# APM32F446 register map
File version: 1.0
CPU: CM4 r0p1, little endian, MPU, FPU, 4 interrupt priority bits
Registers are 32-bit, read-write, reset 0x0 unless marked. A register's access mark holds for its fields unless they carry their own. Offsets are from the block's base; [hi:lo] are bit positions; {n}, {i} and the like mark numbered series; 'fields as' and 'values as' point back to an identical list.

## COMP — Analog Comparators
Base 0x40073000
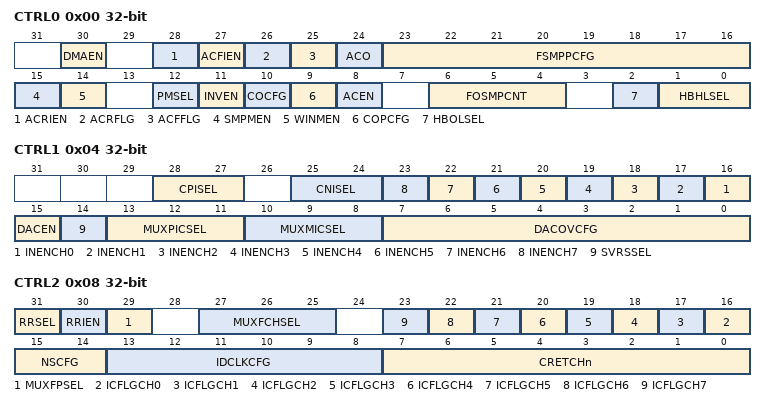
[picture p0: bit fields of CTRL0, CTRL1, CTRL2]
0x00 CTRL0 — COMP Control Register 0
  [30] DMAEN — DMA Enable
    0=DMA is disabled; 1=DMA is enabled
  [28] ACRIEN — Analog Comparator Rising Interrupt Enable
    0=Interrupt is disabled; 1=Interrupt is enabled
  [27] ACFIEN — Analog Comparator Falling Interrupt Enable
    0=Interrupt is disabled; 1=Interrupt is enabled
  [26] ACRFLG — Analog Comparator Rising Flag
    0=A rising edge has not been detected on ACO; 1=A rising edge on ACO has occurred
  [25] ACFFLG — Analog Comparator Falling Flag
    0=A falling edge has not been detected on ACO; 1=A falling edge on ACO has occurred
  [24] ACO ro — Analog Comparator Output
  [23:16] FSMPPCFG — Filter Sample Period Configure
  [15] SMPMEN — Sample Mode Enable
    0=Sampling mode is not selected; 1=Sampling mode is selected
  [14] WINMEN — Windowing Mode Enable
    0=Windowing mode is not selected; 1=Windowing mode is selected
  [12] PMSEL — Power Mode Select
    0=Low Speed (LS) comparison mode is selected; 1=High Speed (HS) comparison mode is selected, in VLPx mode, or Stop mode switched to Low Speed (LS) mode
  [11] INVEN — Invert Enable
    0=Does not invert the comparator output; 1=Inverts the comparator output
  [10] COCFG — Comparator Output Configure
    0=Set COMP to equal COUT (filtered comparator output); 1=Set COMP to equal COUTA (unfiltered comparator output)
  [9] COPCFG — Comparator Output Pin Configure
    0=When COPCFG is 0, the comparator output (after window/filter settings dependent on software configuration) is not available to a packaged pin; 1=When COPCFG is 1, and if the software has configured the comparator to own a packaged pin, the comparator is available in a packaged pin
  [8] ACEN — Analog Comparator Enable
    0=Analog Comparator is disabled; 1=Analog Comparator is enabled
  [6:4] FOSMPCNT — Filter Output Sample Count
    0=Filter is disabled. If SMPMEN = 1, then ACO is a logic zero (this is not a legal state, and is not recommended). If SMPMEN = 0, ACO = ACOA.; 1=1 consecutive sample must agree (comparator output is simply sampled); {v}={v} consecutive samples must agree (v=2..7)
  [2] HBOLSEL — Hard Block Offset Level Select
    0=The comparator hard block output has level 0 offset internally; 1=The comparator hard block output has level 1 offset internally
  [1:0] HBHLSEL — Hard Block Hysteresis Level Select
    {v}=The hard block output has level {v} hysteresis internally (v=0..3)
0x04 CTRL1 — COMP Control Register 1
  [28:27] CPISEL — Comparator Positive Input Select
    0=IN0, from the 8-bit DAC output; 1=IN1, from the analog 8-1 mux
  [25:24] CNISEL — Comparator Negative Input Select
    values as CPISEL
  [n+16] INENCH{n} (n=0..7) — Channel {n} input enable
  [15] DACEN — DAC Enable
    0=DAC is disabled; 1=DAC is enabled
  [14] SVRSSEL — Supply Voltage Reference Source Select
    0=Vin1 is selected as resistor ladder network supply reference Vin; 1=Vin2 is selected as resistor ladder network supply reference Vin
  [13:11] MUXPICSEL — Plus Input MUX Select
    {v}=IN{v} (v=0..7)
  [10:8] MUXMICSEL — Minus Input MUX Select
    {v}=IN{v} (v=0..7)
  [7:0] DACOVCFG — DAC Output Voltage Configure
0x08 CTRL2 — COMP Control Register 2
  [31] RRSEL — Round-Robin Select
    0=Round-robin operation is disabled; 1=Round-robin operation is enabled
  [30] RRIEN — Round-Robin Interrupt Enable
    0=The round-robin interrupt is disabled; 1=The round-robin interrupt is enabled when a comparison result changes from the last sample
  [29] MUXFPSEL — Fixed MUX Port Select
    0=The Plus port is fixed. Only the inputs to the Minus port are swept in each round.; 1=The Minus port is fixed. Only the inputs to the Plus port are swept in each round.
  [27:25] MUXFCHSEL — Fixed MUX Channel Select
    {v}=Channel {v} is selected as the fixed reference input for the fixed mux port (v=0..7)
  [n+16] ICFLGCH{n} (n=0..7) — Channel {n} input changed flag
  [15:14] NSCFG — Number of Sample Clocks Configure
    0=The comparison result is sampled as soon as the active channel is scanned in one round-robin clock; 1=The sampling takes place 1 round-robin clock cycle after the next cycle of the round-robin clock; 2=The sampling takes place 2 round-robin clock cycles after the next cycle of the round-robin clock; 3=The sampling takes place 3 round-robin clock cycles after the next cycle of the round-robin clock
  [13:8] IDCLKCFG — Initialization Delay Clock Configure
    0=The modulus is set to 64 (same with 111111)
  [7:0] CRETCHn — Input Comparison Result of Channel n
